# SF32LB52x register map
File version: 1.0
CPU: CM33 r0p1, little endian, MPU, FPU, 3 interrupt priority bits
Registers are 32-bit, read-write, reset 0x0 unless marked. A register's access mark holds for its fields unless they carry their own. Offsets are from the block's base; [hi:lo] are bit positions.

## LPSYS_RCC
Base 0x40000000
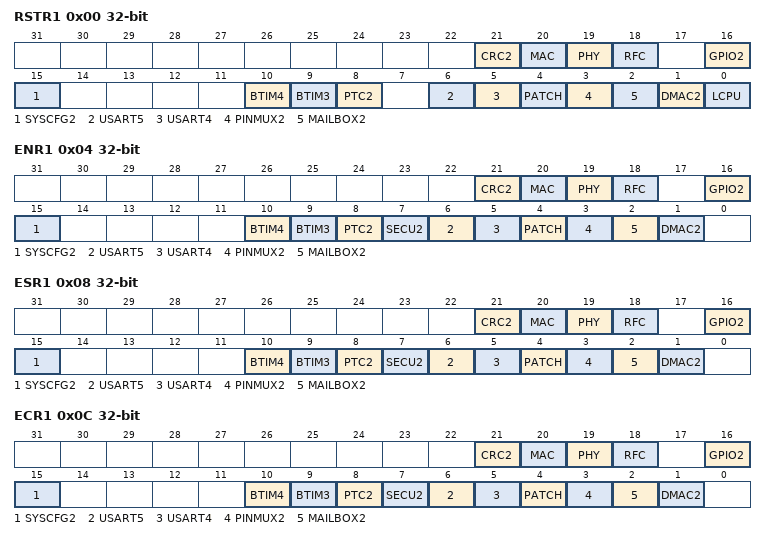
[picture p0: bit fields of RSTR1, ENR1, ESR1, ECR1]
0x00 RSTR1 — Reset Register 1
  [21] CRC2 — 0 - no reset; 1 - reset
  [20] MAC — 0 - no reset; 1 - reset
  [19] PHY — 0 - no reset; 1 - reset
  [18] RFC — 0 - no reset; 1 - reset
  [16] GPIO2 — 0 - no reset; 1 - reset
  [15] SYSCFG2 — 0 - no reset; 1 - reset
  [10] BTIM4 — 0 - no reset; 1 - reset
  [9] BTIM3 — 0 - no reset; 1 - reset
  [8] PTC2 — 0 - no reset; 1 - reset
  [6] USART5 — 0 - no reset; 1 - reset
  [5] USART4 — 0 - no reset; 1 - reset
  [4] PATCH — 0 - no reset; 1 - reset
  [3] PINMUX2 — 0 - no reset; 1 - reset
  [2] MAILBOX2 — 0 - no reset; 1 - reset
  [1] DMAC2 — 0 - no reset; 1 - reset
  [0] LCPU — 0 - no reset; 1 - reset
0x04 ENR1 — Enable Register 1
  [21] CRC2 — 0 - disabled; 1 - enabled
  [20] MAC — 0 - disabled; 1 - enabled
  [19] PHY — 0 - disabled; 1 - enabled
  [18] RFC — 0 - disabled; 1 - enabled
  [16] GPIO2 — 0 - disabled; 1 - enabled
  [15] SYSCFG2 — 0 - disabled; 1 - enabled
  [10] BTIM4 — 0 - disabled; 1 - enabled
  [9] BTIM3 — 0 - disabled; 1 - enabled
  [8] PTC2 — 0 - disabled; 1 - enabled
  [7] SECU2 — 0 - disabled; 1 - enabled
  [6] USART5 — 0 - disabled; 1 - enabled
  [5] USART4 — 0 - disabled; 1 - enabled
  [4] PATCH — 0 - disabled; 1 - enabled
  [3] PINMUX2 — 0 - disabled; 1 - enabled
  [2] MAILBOX2 — 0 - disabled; 1 - enabled
  [1] DMAC2 — 0 - disabled; 1 - enabled
0x08 ESR1 — Enable Set Register 1
  [21] CRC2 — write 1 to set module enable, write 0 has no effect
  [20] MAC — write 1 to set module enable, write 0 has no effect
  [19] PHY — write 1 to set module enable, write 0 has no effect
  [18] RFC — write 1 to set module enable, write 0 has no effect
  [16] GPIO2 — write 1 to set module enable, write 0 has no effect
  [15] SYSCFG2 — write 1 to set module enable, write 0 has no effect
  [10] BTIM4 — write 1 to set module enable, write 0 has no effect
  [9] BTIM3 — write 1 to set module enable, write 0 has no effect
  [8] PTC2 — write 1 to set module enable, write 0 has no effect
  [7] SECU2 — write 1 to set module enable, write 0 has no effect
  [6] USART5 — write 1 to set module enable, write 0 has no effect
  [5] USART4 — write 1 to set module enable, write 0 has no effect
  [4] PATCH — write 1 to set module enable, write 0 has no effect
  [3] PINMUX2 — write 1 to set module enable, write 0 has no effect
  [2] MAILBOX2 — write 1 to set module enable, write 0 has no effect
  [1] DMAC2 — write 1 to set module enable, write 0 has no effect
0x0C ECR1 — Enable Clear Register 1
  [21] CRC2 — write 1 to clear module enable, write 0 has no effect
  [20] MAC — write 1 to clear module enable, write 0 has no effect
  [19] PHY — write 1 to clear module enable, write 0 has no effect
  [18] RFC — write 1 to clear module enable, write 0 has no effect
  [16] GPIO2 — write 1 to clear module enable, write 0 has no effect
  [15] SYSCFG2 — write 1 to clear module enable, write 0 has no effect
  [10] BTIM4 — write 1 to clear module enable, write 0 has no effect
  [9] BTIM3 — write 1 to clear module enable, write 0 has no effect
  [8] PTC2 — write 1 to clear module enable, write 0 has no effect
  [7] SECU2 — write 1 to clear module enable, write 0 has no effect
  [6] USART5 — write 1 to clear module enable, write 0 has no effect
  [5] USART4 — write 1 to clear module enable, write 0 has no effect
  [4] PATCH — write 1 to clear module enable, write 0 has no effect
  [3] PINMUX2 — write 1 to clear module enable, write 0 has no effect
  [2] MAILBOX2 — write 1 to clear module enable, write 0 has no effect
  [1] DMAC2 — write 1 to clear module enable, write 0 has no effect
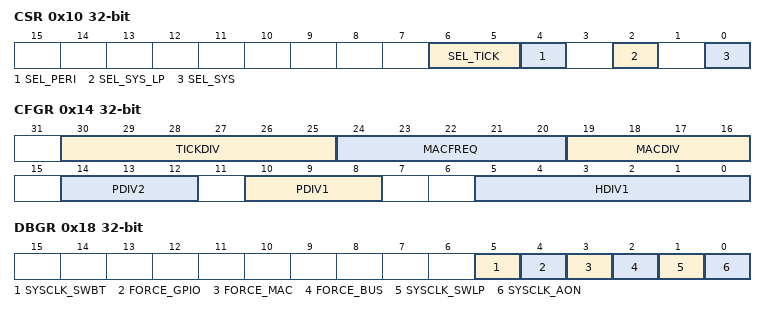
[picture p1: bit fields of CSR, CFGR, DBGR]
0x10 CSR — Clock Select Register
  [6:5] SEL_TICK — select clock source for systick reference 0 - clk_rtc; 1 - reserved; 2 - clk_hrc48; 3 - clk_hxt48
  [4] SEL_PERI — select clk_peri_lpsys source 0 - clk_hrc48; 1 - clk_hxt48
  [2] SEL_SYS_LP — select clk_lpsys source 0 - selected by SEL_SYS; 1 - clk_wdt
  [0] SEL_SYS — select clk_lpsys source 0 - clk_hrc48; 1 - clk_hxt48
0x14 CFGR — Clock Configuration Register
  [30:25] TICKDIV — systick reference clock is systick reference clock source (selected by SEL_TICK) devided by TICKDIV
  [24:20] MACFREQ — clock frequency of MAC clock
  [19:16] MACDIV — MAC clock divider MACCLK = hclk_lpsys / MACDIV
  [14:12] PDIV2 — pclk2_lpsys = hclk_lpsys / (2^PDIV2), by default divided by 32
  [10:8] PDIV1 — pclk1_lpsys = hclk_lpsys / (2^PDIV1), by default divided by 2
  [5:0] HDIV1 — hclk_lpsys = clk_lpsys / HDIV if HDIV=0, hclk_lpsys = clk_lpsys
0x18 DBGR — Debug Register
  [5] SYSCLK_SWBT — If set to 1, clk_lpsys will: switch from clk_hrc48 to clk_hxt48 when MAC active; switch from clk_hxt48 to clk_hrc48 when MAC sleep;
  [4] FORCE_GPIO — for debug only
  [3] FORCE_MAC — for debug only
  [2] FORCE_BUS — for debug only
  [1] SYSCLK_SWLP — for debug only
  [0] SYSCLK_AON — for debug only
